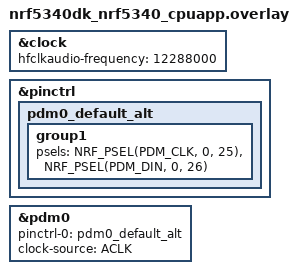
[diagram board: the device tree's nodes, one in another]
/*
 * Copyright (c) 2021 Nordic Semiconductor ASA
 *
 * SPDX-License-Identifier: Apache-2.0
 */

&clock {
	hfclkaudio-frequency = <12288000>;
};

&pinctrl {
	pdm0_default_alt: pdm0_default_alt {
		group1 {
			psels = <NRF_PSEL(PDM_CLK, 0, 25)>,
				<NRF_PSEL(PDM_DIN, 0, 26)>;
		};
	};
};

dmic_dev: &pdm0 {
	status = "okay";
	pinctrl-0 = <&pdm0_default_alt>;
	pinctrl-names = "default";
	clock-source = "ACLK";
};
